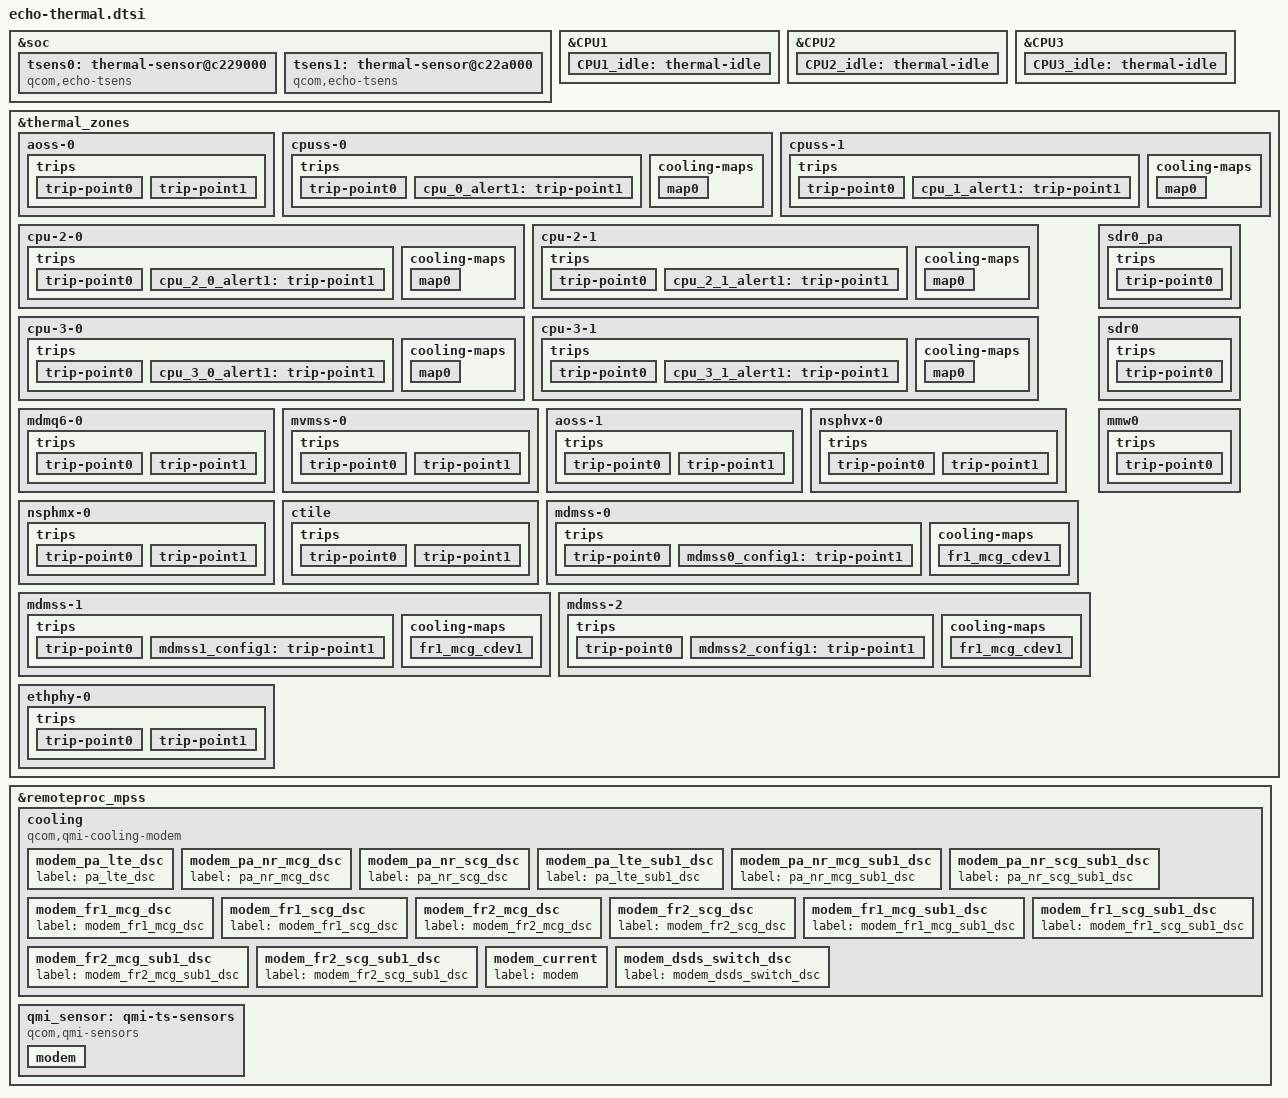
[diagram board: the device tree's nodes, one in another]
// SPDX-License-Identifier: BSD-3-Clause
/*
 * Copyright (c) Qualcomm Technologies, Inc. and/or its subsidiaries.
 */
#include <dt-bindings/thermal/thermal_qti.h>

&soc {

	tsens0: thermal-sensor@c229000 {
		compatible = "qcom,echo-tsens", "qcom,tsens-v2";
		reg = <0x0 0xc229000 0x0 0x1ff>,
			  <0x0 0x0c222000 0x0 0x1ff>;
		interrupts = <GIC_SPI 173 IRQ_TYPE_LEVEL_HIGH>,
					 <GIC_SPI 333 IRQ_TYPE_LEVEL_HIGH>;
		#qcom,sensors = <9>;
		interrupt-names = "uplow", "critical";
		#thermal-sensor-cells = <1>;
	};

	tsens1: thermal-sensor@c22a000 {
		compatible = "qcom,echo-tsens", "qcom,tsens-v2";
		reg = <0x0 0xc22a000 0x0 0x1ff>,
			  <0x0 0xc223000 0x0 0x1ff>;
		interrupts = <GIC_SPI 174 IRQ_TYPE_LEVEL_HIGH>,
				     <GIC_SPI 665 IRQ_TYPE_LEVEL_HIGH>;
		#qcom,sensors = <9>;
		interrupt-names = "uplow", "critical";
		#thermal-sensor-cells = <1>;
	};
};

&CPU1 {
	#cooling-cells = <2>;
	CPU1_idle: thermal-idle {
		#cooling-cells = <2>;
		duration-us = <800000>;
		exit-latency-us = <10000>;
	};
};

&CPU2 {
	#cooling-cells = <2>;
	CPU2_idle: thermal-idle {
		#cooling-cells = <2>;
		duration-us = <800000>;
		exit-latency-us = <10000>;
	};
};

&CPU3 {
	#cooling-cells = <2>;
	CPU3_idle: thermal-idle {
		#cooling-cells = <2>;
		duration-us = <800000>;
		exit-latency-us = <10000>;
	};
};

&thermal_zones {

	aoss-0 {
		polling-delay-passive = <0>;
		polling-delay = <0>;
		thermal-sensors = <&tsens0 0>;
		trips {
			trip-point0 {
				temperature = <135000>;
				hysteresis = <5000>;
				type = "passive";
			};

			trip-point1 {
				temperature = <125000>;
				hysteresis = <5000>;
				type = "passive";
			};

		};
	};

	cpuss-0 {
		polling-delay-passive = <0>;
		polling-delay = <0>;
		thermal-sensors = <&tsens0 1>;
		trips {
			trip-point0 {
				temperature = <135000>;
				hysteresis = <5000>;
				type = "passive";
			};

			cpu_0_alert1: trip-point1 {
				temperature = <115000>;
				hysteresis = <5000>;
				type = "passive";
			};

		};

		cooling-maps {
			map0 {
				trip = <&cpu_0_alert1>;
				cooling-device = <&CPU1_idle 100 100>;
			};
		};
	};

	cpuss-1 {
		polling-delay-passive = <0>;
		polling-delay = <0>;
		thermal-sensors = <&tsens0 2>;
		trips {
			trip-point0 {
				temperature = <135000>;
				hysteresis = <5000>;
				type = "passive";
			};

			cpu_1_alert1: trip-point1 {
				temperature = <115000>;
				hysteresis = <5000>;
				type = "passive";
			};

		};

		cooling-maps {
			map0 {
				trip = <&cpu_1_alert1>;
				cooling-device = <&CPU1_idle 100 100>;
			};
		};
	};

	cpu-2-0 {
		polling-delay-passive = <0>;
		polling-delay = <0>;
		thermal-sensors = <&tsens0 3>;
		trips {
			trip-point0 {
				temperature = <135000>;
				hysteresis = <5000>;
				type = "passive";
			};

			cpu_2_0_alert1: trip-point1 {
				temperature = <115000>;
				hysteresis = <5000>;
				type = "passive";
			};

		};

		cooling-maps {
			map0 {
				trip = <&cpu_2_0_alert1>;
				cooling-device = <&CPU2_idle 100 100>;
			};
		};
	};

	cpu-2-1 {
		polling-delay-passive = <0>;
		polling-delay = <0>;
		thermal-sensors = <&tsens0 4>;
		trips {
			trip-point0 {
				temperature = <135000>;
				hysteresis = <5000>;
				type = "passive";
			};

			cpu_2_1_alert1: trip-point1 {
				temperature = <115000>;
				hysteresis = <5000>;
				type = "passive";
			};

		};

		cooling-maps {
			map0 {
				trip = <&cpu_2_1_alert1>;
				cooling-device = <&CPU2_idle 100 100>;
			};
		};
	};

	cpu-3-0 {
		polling-delay-passive = <0>;
		polling-delay = <0>;
		thermal-sensors = <&tsens0 5>;
		trips {
			trip-point0 {
				temperature = <135000>;
				hysteresis = <5000>;
				type = "passive";
			};

			cpu_3_0_alert1: trip-point1 {
				temperature = <115000>;
				hysteresis = <5000>;
				type = "passive";
			};

		};

		cooling-maps {
			map0 {
				trip = <&cpu_3_0_alert1>;
				cooling-device = <&CPU3_idle 100 100>;
			};
		};
	};

	cpu-3-1 {
		polling-delay-passive = <0>;
		polling-delay = <0>;
		thermal-sensors = <&tsens0 6>;
		trips {
			trip-point0 {
				temperature = <135000>;
				hysteresis = <5000>;
				type = "passive";
			};

			cpu_3_1_alert1: trip-point1 {
				temperature = <115000>;
				hysteresis = <5000>;
				type = "passive";
			};

		};

		cooling-maps {
			map0 {
				trip = <&cpu_3_1_alert1>;
				cooling-device = <&CPU3_idle 100 100>;
			};
		};
	};

	mdmq6-0 {
		polling-delay-passive = <0>;
		polling-delay = <0>;
		thermal-sensors = <&tsens0 7>;
		trips {
			trip-point0 {
				temperature = <135000>;
				hysteresis = <5000>;
				type = "passive";
			};

			trip-point1 {
				temperature = <125000>;
				hysteresis = <5000>;
				type = "passive";
			};

		};
	};

	mvmss-0 {
		polling-delay-passive = <0>;
		polling-delay = <0>;
		thermal-sensors = <&tsens0 8>;
		trips {
			trip-point0 {
				temperature = <135000>;
				hysteresis = <5000>;
				type = "passive";
			};

			trip-point1 {
				temperature = <125000>;
				hysteresis = <5000>;
				type = "passive";
			};

		};
	};

	aoss-1 {
		polling-delay-passive = <0>;
		polling-delay = <0>;
		thermal-sensors = <&tsens1 0>;
		trips {
			trip-point0 {
				temperature = <135000>;
				hysteresis = <5000>;
				type = "passive";
			};

			trip-point1 {
				temperature = <125000>;
				hysteresis = <5000>;
				type = "passive";
			};

		};
	};

	nsphvx-0 {
		polling-delay-passive = <0>;
		polling-delay = <0>;
		thermal-sensors = <&tsens1 1>;
		trips {
			trip-point0 {
				temperature = <135000>;
				hysteresis = <5000>;
				type = "passive";
			};

			trip-point1 {
				temperature = <125000>;
				hysteresis = <5000>;
				type = "passive";
			};

		};
	};

	nsphmx-0 {
		polling-delay-passive = <0>;
		polling-delay = <0>;
		thermal-sensors = <&tsens1 2>;
		trips {
			trip-point0 {
				temperature = <135000>;
				hysteresis = <5000>;
				type = "passive";
			};

			trip-point1 {
				temperature = <125000>;
				hysteresis = <5000>;
				type = "passive";
			};

		};
	};

	ctile {
		polling-delay-passive = <0>;
		polling-delay = <0>;
		thermal-sensors = <&tsens1 4>;
		trips {
			trip-point0 {
				temperature = <135000>;
				hysteresis = <5000>;
				type = "passive";
			};

			trip-point1 {
				temperature = <125000>;
				hysteresis = <5000>;
				type = "passive";
			};

		};
	};

	mdmss-0 {
		polling-delay-passive = <0>;
		polling-delay = <0>;
		thermal-sensors = <&tsens1 5>;
		trips {
			trip-point0 {
				temperature = <135000>;
				hysteresis = <5000>;
				type = "passive";
			};

			mdmss0_config1: trip-point1 {
				temperature = <115000>;
				hysteresis = <5000>;
				type = "passive";
			};

		};

		cooling-maps {
			fr1_mcg_cdev1 {
				trip = <&mdmss0_config1>;
				cooling-device = <&modem_fr1_mcg_dsc 255 255>;
			};
		};
	};

	mdmss-1 {
		polling-delay-passive = <0>;
		polling-delay = <0>;
		thermal-sensors = <&tsens1 6>;
		trips {
			trip-point0 {
				temperature = <135000>;
				hysteresis = <5000>;
				type = "passive";
			};

			mdmss1_config1: trip-point1 {
				temperature = <115000>;
				hysteresis = <5000>;
				type = "passive";
			};

		};

		cooling-maps {
			fr1_mcg_cdev1 {
				trip = <&mdmss1_config1>;
				cooling-device = <&modem_fr1_mcg_dsc 255 255>;
			};
		};
	};

	mdmss-2 {
		polling-delay-passive = <0>;
		polling-delay = <0>;
		thermal-sensors = <&tsens1 7>;
		trips {
			trip-point0 {
				temperature = <135000>;
				hysteresis = <5000>;
				type = "passive";
			};

			mdmss2_config1: trip-point1 {
				temperature = <115000>;
				hysteresis = <5000>;
				type = "passive";
			};

		};

		cooling-maps {
			fr1_mcg_cdev1 {
				trip = <&mdmss2_config1>;
				cooling-device = <&modem_fr1_mcg_dsc 255 255>;
			};
		};
	};

	ethphy-0 {
		polling-delay-passive = <0>;
		polling-delay = <0>;
		thermal-sensors = <&tsens1 8>;
		trips {
			trip-point0 {
				temperature = <135000>;
				hysteresis = <5000>;
				type = "passive";
			};

			trip-point1 {
				temperature = <125000>;
				hysteresis = <5000>;
				type = "passive";
			};

		};
	};

};

&remoteproc_mpss {
	cooling {
		compatible = "qcom,qmi-cooling-modem";

		modem_pa_lte_dsc: modem_pa_lte_dsc {
			label = "pa_lte_dsc";
			#cooling-cells = <2>;
		};

		modem_pa_nr_mcg_dsc: modem_pa_nr_mcg_dsc {
			label = "pa_nr_mcg_dsc";
			#cooling-cells = <2>;
		};

		modem_pa_nr_scg_dsc: modem_pa_nr_scg_dsc {
			label = "pa_nr_scg_dsc";
			#cooling-cells = <2>;
		};

		modem_pa_lte_sub1_dsc: modem_pa_lte_sub1_dsc {
			label = "pa_lte_sub1_dsc";
			#cooling-cells = <2>;
		};

		modem_pa_nr_mcg_sub1_dsc: modem_pa_nr_mcg_sub1_dsc {
			label = "pa_nr_mcg_sub1_dsc";
			#cooling-cells = <2>;
		};

		modem_pa_nr_scg_sub1_dsc: modem_pa_nr_scg_sub1_dsc {
			label = "pa_nr_scg_sub1_dsc";
			#cooling-cells = <2>;
		};

		modem_fr1_mcg_dsc: modem_fr1_mcg_dsc {
			label = "modem_fr1_mcg_dsc";
			#cooling-cells = <2>;
		};

		modem_fr1_scg_dsc: modem_fr1_scg_dsc {
			label = "modem_fr1_scg_dsc";
			#cooling-cells = <2>;
		};

		modem_fr2_mcg_dsc: modem_fr2_mcg_dsc {
			label = "modem_fr2_mcg_dsc";
			#cooling-cells = <2>;
		};

		modem_fr2_scg_dsc: modem_fr2_scg_dsc {
			label = "modem_fr2_scg_dsc";
			#cooling-cells = <2>;
		};

		modem_fr1_mcg_sub1_dsc: modem_fr1_mcg_sub1_dsc {
			label = "modem_fr1_mcg_sub1_dsc";
			#cooling-cells = <2>;
		};

		modem_fr1_scg_sub1_dsc: modem_fr1_scg_sub1_dsc {
			label = "modem_fr1_scg_sub1_dsc";
			#cooling-cells = <2>;
		};

		modem_fr2_mcg_sub1_dsc: modem_fr2_mcg_sub1_dsc {
			label = "modem_fr2_mcg_sub1_dsc";
			#cooling-cells = <2>;
		};

		modem_fr2_scg_sub1_dsc: modem_fr2_scg_sub1_dsc {
			label = "modem_fr2_scg_sub1_dsc";
			#cooling-cells = <2>;
		};

		modem_current: modem_current {
			label = "modem";
			#cooling-cells = <2>;
		};

		modem_dsds_switch_dsc: modem_dsds_switch_dsc {
			label = "modem_dsds_switch_dsc";
			#cooling-cells = <2>;
		};
	};

	qmi_sensor: qmi-ts-sensors {
		compatible = "qcom,qmi-sensors";
		#thermal-sensor-cells = <1>;

		modem {
			qcom,instance-id = <QMI_MODEM_INST_ID>;
			qcom,qmi-sensor-names = "sdr0_pa",
						"sdr0",
						"mmw0";
		};
	};
};

&thermal_zones {
	sdr0_pa {
		polling-delay-passive = <0>;
		polling-delay = <0>;
		thermal-sensors = <&qmi_sensor
				(QMI_MODEM_INST_ID+QMI_SDR0_PA)>;
		trips {
			trip-point0 {
				temperature = <125000>;
				hysteresis = <1000>;
				type = "passive";
			};
		};
	};

	sdr0 {
		polling-delay-passive = <0>;
		polling-delay = <0>;
		thermal-sensors = <&qmi_sensor
				(QMI_MODEM_INST_ID+QMI_SDR0)>;
		trips {
			trip-point0 {
				temperature = <125000>;
				hysteresis = <1000>;
				type = "passive";
			};

		};
	};

	mmw0 {
		polling-delay-passive = <0>;
		polling-delay = <0>;
		thermal-sensors = <&qmi_sensor
				(QMI_MODEM_INST_ID+QMI_MMW0)>;
		trips {
			trip-point0 {
				temperature = <125000>;
				hysteresis = <1000>;
				type = "passive";
			};
		};
	};
};
